# MK11D5WS register map
File version: 1.6
Registers are 32-bit, read-write, reset 0x0 unless marked. A register's access mark holds for its fields unless they carry their own. Offsets are from the block's base; [hi:lo] are bit positions; {n}, {i} and the like mark numbered series; 'fields as' and 'values as' point back to an identical list.

## PORTA — Pin Control and Interrupts
Base 0x40049000; register names take the prefix PORTA_
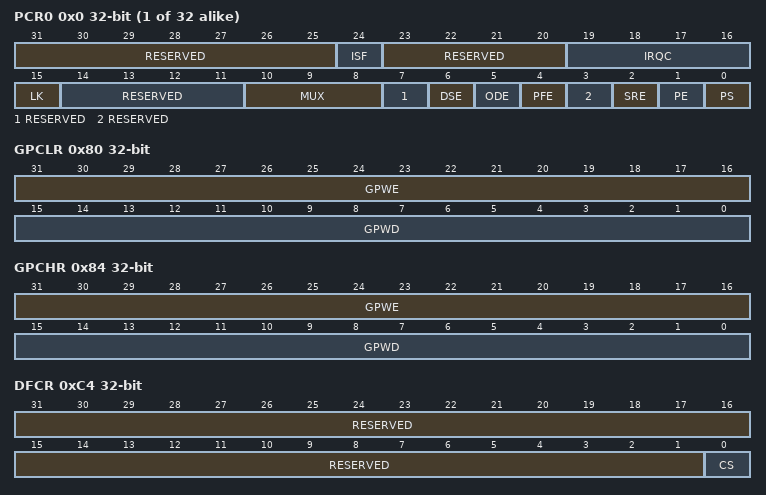
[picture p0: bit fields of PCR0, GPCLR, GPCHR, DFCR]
{0x0+4i} PCR{i} (i=0..31) — Pin Control Register n
  [31:25] RESERVED ro
  [24] ISF — Interrupt Status Flag
    0=Configured interrupt is not detected; 1=Configured interrupt is detected. If the pin is configured to generate a DMA request, then the corresponding flag will be cleared automatically at the completion of the requested DMA transfer. Otherwise, the flag remains set until a logic one is written to the flag. If the pin is configured for a level sensitive interrupt and the pin remains asserted, then the flag is set again immediately after it is cleared.
  [23:20] RESERVED ro
  [19:16] IRQC — Interrupt Configuration
    0=Interrupt/DMA request disabled; 1=DMA request on rising edge; 2=DMA request on falling edge; 3=DMA request on either edge; 8=Interrupt when logic zero; 9=Interrupt on rising edge; 10=Interrupt on falling edge; 11=Interrupt on either edge; 12=Interrupt when logic one
  [15] LK — Lock Register
    0=Pin Control Register fields [15:0] are not locked; 1=Pin Control Register fields [15:0] are locked and cannot be updated until the next system reset
  [14:11] RESERVED ro
  [10:8] MUX — Pin Mux Control
    0=Pin disabled (analog); 1=Alternative 1 (GPIO); {v}=Alternative {v} (chip-specific) (v=2..7)
  [7] RESERVED ro
  [6] DSE — Drive Strength Enable
    0=Low drive strength is configured on the corresponding pin, if pin is configured as a digital output; 1=High drive strength is configured on the corresponding pin, if pin is configured as a digital output
  [5] ODE — Open Drain Enable
    0=Open drain output is disabled on the corresponding pin; 1=Open drain output is enabled on the corresponding pin, if the pin is configured as a digital output
  [4] PFE — Passive Filter Enable
    0=Passive input filter is disabled on the corresponding pin; 1=Passive input filter is enabled on the corresponding pin, if the pin is configured as a digital input. Refer to the device data sheet for filter characteristics.
  [3] RESERVED ro
  [2] SRE — Slew Rate Enable
    0=Fast slew rate is configured on the corresponding pin, if the pin is configured as a digital output; 1=Slow slew rate is configured on the corresponding pin, if the pin is configured as a digital output
  [1] PE — Pull Enable
    0=Internal pullup or pulldown resistor is not enabled on the corresponding pin; 1=Internal pullup or pulldown resistor is enabled on the corresponding pin, if the pin is configured as a digital input
  [0] PS — Pull Select
    0=Internal pulldown resistor is enabled on the corresponding pin, if the corresponding Port Pull Enable field is set; 1=Internal pullup resistor is enabled on the corresponding pin, if the corresponding Port Pull Enable field is set
0x80 GPCLR wo — Global Pin Control Low Register
  [31:16] GPWE — Global Pin Write Enable
    0=Corresponding Pin Control Register is not updated with the value in GPWD; 1=Corresponding Pin Control Register is updated with the value in GPWD
  [15:0] GPWD — Global Pin Write Data
0x84 GPCHR wo — Global Pin Control High Register
  fields as GPCLR
0xA0 ISFR — Interrupt Status Flag Register
  [31:0] ISF — Interrupt Status Flag
    values as PCR0.ISF
0xC0 DFER — Digital Filter Enable Register
  [31:0] DFE — Digital Filter Enable
    0=Digital filter is disabled on the corresponding pin and output of the digital filter is reset to zero; 1=Digital filter is enabled on the corresponding pin, if the pin is configured as a digital input
0xC4 DFCR — Digital Filter Clock Register
  [31:1] RESERVED ro
  [0] CS — Clock Source
    0=Digital filters are clocked by the bus clock; 1=Digital filters are clocked by the 1 kHz LPO clock
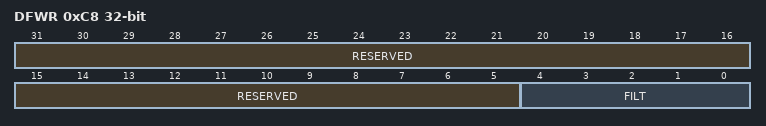
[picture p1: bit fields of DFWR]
0xC8 DFWR — Digital Filter Width Register
  [31:5] RESERVED ro
  [4:0] FILT — Filter Length

## PORTB — Pin Control and Interrupts
Base 0x4004A000; register names take the prefix PORTB_
Registers as PORTA.

## PORTC — Pin Control and Interrupts
Base 0x4004B000; register names take the prefix PORTC_
Registers as PORTA.

## PORTD — Pin Control and Interrupts
Base 0x4004C000; register names take the prefix PORTD_
Registers as PORTA.

## PORTE — Pin Control and Interrupts
Base 0x4004D000; register names take the prefix PORTE_
Registers as PORTA.
